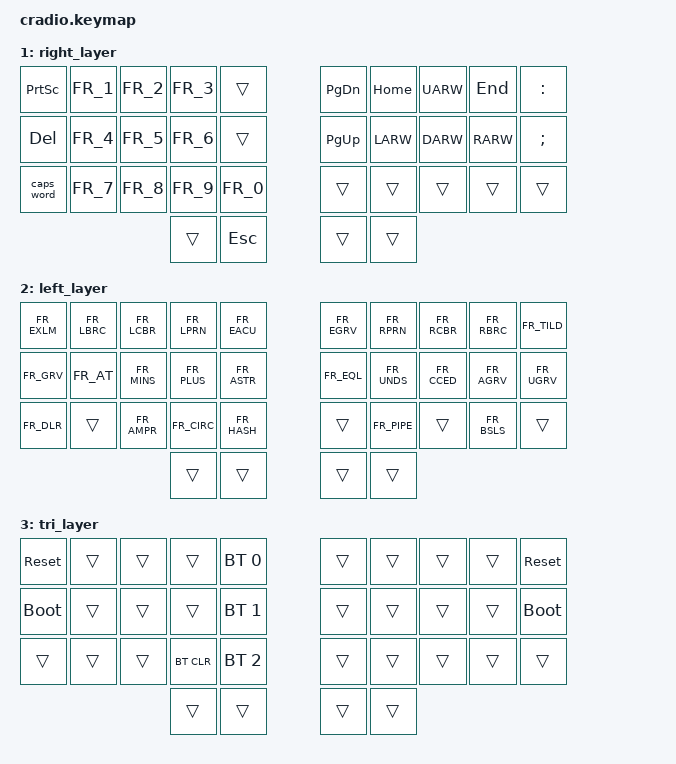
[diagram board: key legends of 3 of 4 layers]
// Copyright (c) 2022 The ZMK Contributors
// SPDX-License-Identifier: MIT

#include <behaviors.dtsi>
#include <dt-bindings/zmk/keys.h>
#include <dt-bindings/zmk/bt.h>
#include "keymap_french.h"

// Home row mods macro
#define HRML(k1,k2,k3,k4) &ht LSHFT k1  &ht LALT k2  &ht LCTRL k3  &ht LGUI k4
#define HRMR(k1,k2,k3,k4) &ht RGUI k1  &ht RCTRL k2  &ht RALT k3  &ht RSHFT k4

/ {
    behaviors {
        ht: hold_tap {
            compatible = "zmk,behavior-hold-tap";
            #binding-cells = <2>;
            flavor = "balanced";
            tapping-term-ms = <200>;
            quick-tap-ms = <150>;
            require-prior-idle-ms = <150>;
            bindings = <&kp>, <&kp>;
        };
    };

    conditional_layers {
        compatible = "zmk,conditional-layers";
        tri_layer {
            if-layers = <1 2>;
            then-layer = <3>;
        };
    };

    keymap {
        compatible = "zmk,keymap";
        default_layer {
            bindings = <
        //╭──────────┬──────────┬──────────┬──────────┬──────────╮   ╭──────────┬──────────┬──────────┬──────────┬──────────╮
        //│  Q       │  W       │  F       │  P       │  B       │   │  J       │  L       │  U       │  Y       │  K       │
            &kp FR_Q   &kp FR_W   &kp FR_F   &kp FR_P   &kp FR_B       &kp FR_J   &kp FR_L   &kp FR_U   &kp FR_Y   &kp FR_K
        //├──────────┼──────────┼──────────┼──────────┼──────────┤   ├──────────┼──────────┼──────────┼──────────┼──────────┤
        //│  A       │  R       │  S       │  T       │  G       │   │  M       │  N       │  E       │  I       │ O        │
            HRML(FR_A,  FR_R,      FR_S,      FR_T)      &kp FR_G       &kp FR_M   HRMR(FR_N,  FR_E,     FR_I,     FR_O)
        //├──────────┼──────────┼──────────┼──────────┼──────────┤   ├──────────┼──────────┼──────────┼──────────┼──────────┤
        //│  Z       │  X       │  C       │  D       │  V       │   │  H       │  , ?     │ ; .      │ : /      │ ! §      │
            &kp FR_Z   &kp FR_X  &kp FR_C   &kp FR_D   &kp FR_V        &kp FR_H  &kp FR_COMM &kp FR_SCLN &kp FR_COLN &kp FR_EXLM
        //╰──────────┴──────────┴──────────┼──────────┼──────────┤   ├──────────┼──────────┼──────────┴──────────┴──────────╯
                                            &lt 2 TAB   &kp ENTER     &kp SPACE  &lt 1 BSPC
        //                                 ╰──────────┴──────────╯   ╰──────────┴──────────╯
            >;
        };

        right_layer {
            bindings = <
        //╭──────────┬──────────┬──────────┬──────────┬──────────╮   ╭──────────┬──────────┬──────────┬──────────┬──────────╮
        //│ IMPECR   │  1       │  2       │  3       │          │   │ PAGE DN  │ HOME     │ UP       │ END      │  :       │
           &kp PSCRN   &kp FR_1   &kp FR_2   &kp FR_3   &trans         &kp PG_DN   &kp HOME  &kp UARW  &kp END    &kp COLON
        //├──────────┼──────────┼──────────┼──────────┼──────────┤   ├──────────┼──────────┼──────────┼──────────┼──────────┤
        //│ DELETE   │  4       │  5       │  6       │          │   │ PAGE UP  │ LEFT     │ UP       │ RIGHT    │  ;       │
            &kp DEL    &kp FR_4   &kp FR_5   &kp FR_6   &trans         &kp PG_UP  &kp LARW   &kp DARW   &kp RARW   &kp SEMI
        //├──────────┼──────────┼──────────┼──────────┼──────────┤   ├──────────┼──────────┼──────────┼──────────┼──────────┤
        //│ CAPS     │  7       │  8       │  9       │  0       │   │          │          │          │          │          │
           &caps_word  &kp FR_7   &kp FR_8   &kp FR_9   &kp FR_0       &trans     &trans     &trans     &trans     &trans
        //╰──────────┴──────────┴──────────┼──────────┼──────────┤   ├──────────┼──────────┼──────────┴──────────┴──────────╯
                                             &trans     &kp ESC        &trans     &trans
        //                                 ╰──────────┴──────────╯   ╰──────────┴──────────╯
            >;
        };

        left_layer {
            bindings = <
        //╭──────────┬──────────┬──────────┬──────────┬──────────╮   ╭──────────┬──────────┬──────────  ┬──────────┬──────────╮
        //│  !       │  [       │  {       │  (       │  é       │   │  è       │  )       │  }         │  ]       │  ~       │
           &kp FR_EXLM   &kp FR_LBRC &kp FR_LCBR &kp FR_LPRN &kp FR_EACU  &kp FR_EGRV &kp FR_RPRN &kp FR_RCBR &kp FR_RBRC &kp FR_TILD
        //├──────────┼──────────┼──────────┼──────────┼──────────┤   ├──────────┼──────────┼──────────  ┼──────────┼──────────┤
        //│  `       │  @       │  -       │  +       │  *       │   │  =       │  _       │  ç         │  à       │  ù       │
           &kp FR_GRV  &kp FR_AT &kp FR_MINS &kp FR_PLUS &kp FR_ASTR  &kp FR_EQL &kp FR_UNDS &kp FR_CCED &kp FR_AGRV &kp FR_UGRV
        //├──────────┼──────────┼──────────┼──────────┼──────────┤   ├──────────┼──────────┼──────────  ┼──────────┼──────────┤
        //│  $       │  €       │  &       │  ^       │  #       │   │          │  |       │            │  \       │          │
        //  &kp FR_DLR &kp FR_EURO &kp FR_AMPR &kp FR_Q  &kp FR_Q        &kp FR_Q  &kp FR_PIPE  &trans     &kp FR_BSLS  &trans
           &kp FR_DLR &trans    &kp FR_AMPR &kp FR_CIRC &kp FR_HASH      &trans    &kp FR_PIPE  &trans     &kp FR_BSLS   &trans
        //╰──────────┴──────────┴──────────┼──────────┼──────────┤   ├──────────┼──────────┼──────────  ┴──────────┴──────────╯
                                             &trans     &trans         &trans     &trans
        //                                 ╰──────────┴──────────╯   ╰──────────┴──────────╯
            >;
        };

        tri_layer {
            bindings = <
        //╭──────────┬──────────┬──────────┬──────────┬──────────╮   ╭──────────┬──────────┬──────────┬──────────┬──────────╮
        //│ RESET    │          │          │          │PROFILE 0 │   │          │          │          │          │  RESET   │
           &sys_reset  &trans     &trans     &trans    &bt BT_SEL 0    &trans     &trans     &trans     &trans    &sys_reset
        //├──────────┼──────────┼──────────┼──────────┼──────────┤   ├──────────┼──────────┼──────────┼──────────┼──────────┤
        //│BOOTLOADER│          │          │          │PROFILE 1 │   │          │          │          │          │BOOTLOADER│
          &bootloader  &trans     &trans     &trans    &bt BT_SEL 1    &trans     &trans     &trans     &trans    &bootloader
        //├──────────┼──────────┼──────────┼──────────┼──────────┤   ├──────────┼──────────┼──────────┼──────────┼──────────┤
        //│          │          │          │ CLEAR BT │PROFILE 2 │   │          │          │          │          │          │
            &trans     &trans     &trans    &bt BT_CLR &bt BT_SEL 2    &trans     &trans     &trans     &trans     &trans
        //╰──────────┴──────────┴──────────┼──────────┼──────────┤   ├──────────┼──────────┼──────────┴──────────┴──────────╯
                                             &trans     &trans         &trans     &trans
        //                                 ╰──────────┴──────────╯   ╰──────────┴──────────╯
            >;
        };
    };
};
